VERSION ""

NS_ :

BS_:

BU_: MASTER_BMS SUB_BMS
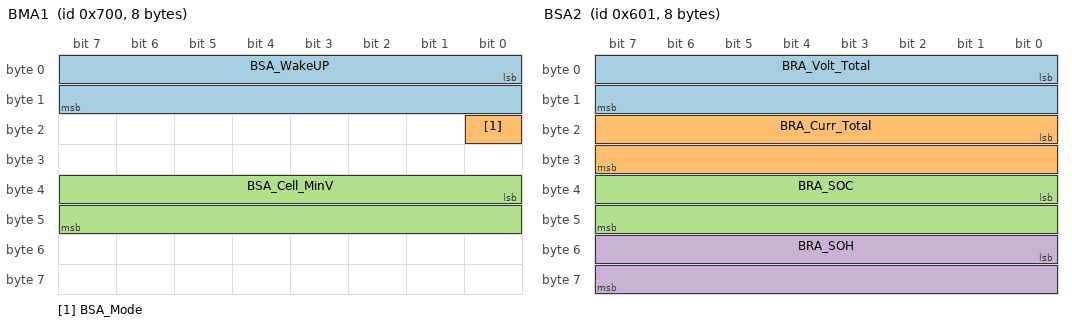
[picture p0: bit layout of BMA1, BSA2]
BO_ 1792 BMA1: 8 MASTER_BMS
 SG_ BSA_WakeUP : 0|16@1+ (1.0,0) [0.0|1.0] "flag"  SUB_BMS
 SG_ BSA_Mode : 16|1@1+ (1.0,0) [0.0|1.0] "flag"  SUB_BMS
 SG_ BSA_Cell_MinV : 32|16@1+ (0.001,0) [2.8|4.5] "V"  SUB_BMS
BO_ 1536 BSA1: 8 SUB_BMS
 SG_ BRA_Normal_Volt : 16|16@1+ (0.1,0) [0.0|100.0] "V"  MASTER_BMS
 SG_ BRA_Capacity : 32|16@1+ (0.1,0) [30.0|60.0] "Ah"  MASTER_BMS
BO_ 1537 BSA2: 8 SUB_BMS
 SG_ BRA_Volt_Total : 0|16@1+ (0.1,0) [40.0|120.0] "V"  MASTER_BMS
 SG_ BRA_Curr_Total : 16|16@1- (0.1,0) [-500.0|500.0] "A"  MASTER_BMS
 SG_ BRA_SOC : 32|16@1+ (0.1,0) [0.0|120.0] "%"  MASTER_BMS
 SG_ BRA_SOH : 48|16@1- (0.1,0) [0.0|100.0] "%"  MASTER_BMS
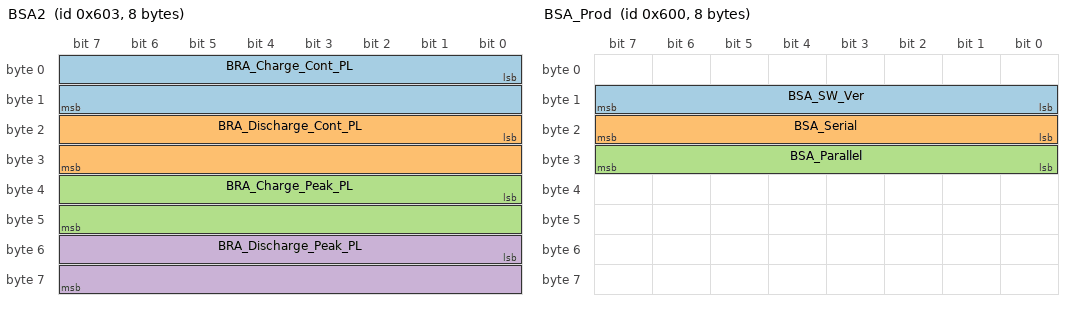
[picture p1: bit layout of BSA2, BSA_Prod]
BO_ 1539 BSA2: 8 SUB_BMS
 SG_ BRA_Charge_Cont_PL : 0|16@1+ (1.0,0) [10.0|5000.0] "W"  MASTER_BMS
 SG_ BRA_Discharge_Cont_PL : 16|16@1+ (1.0,0) [10.0|30000.0] "W"  MASTER_BMS
 SG_ BRA_Charge_Peak_PL : 32|16@1+ (1.0,0) [10.0|6000.0] "W"  MASTER_BMS
 SG_ BRA_Discharge_Peak_PL : 48|16@1+ (1.0,0) [10.0|40000.0] "W"  MASTER_BMS
BO_ 1543 BSA4: 8 SUB_BMS
 SG_ BSA_Cell_MaxV Location : 0|16@1+ (1.0,0) [0.0|20.0] "BM"  MASTER_BMS
 SG_ BSA_Cell_MinV Location : 16|16@1+ (0.01,0) [57.599999999999994|108.0] "V"  MASTER_BMS
 SG_ BSA_Cell_MaxT Location : 32|16@1+ (0.001,0) [2.5|4.5] "V"  MASTER_BMS
 SG_ BSA_Cell_MinT Location : 48|16@1+ (0.001,0) [2.5|4.5] "V"  MASTER_BMS
BO_ 1538 BSA_Calc: 8 SUB_BMS
 SG_ BSA_Divice_Status : 0|8@1+ (1.0,0) [0.0|4.0] "State"  MASTER_BMS
BO_ 1536 BSA_Prd: 8 SUB_BMS
 SG_ BSA_Type : 0|8@1+ (1.0,0) [0.0|10.0] ""  MASTER_BMS
BO_ 1536 BSA_Prod: 8 SUB_BMS
 SG_ BSA_SW_Ver : 8|8@1- (1.0,0) [1.0|10.0] "VER"  MASTER_BMS
 SG_ BSA_Serial : 16|8@1- (1.0,0) [0.0|200.0] "S"  MASTER_BMS
 SG_ BSA_Parallel : 24|8@1+ (1.0,0) [0.0|10.0] "P"  MASTER_BMS
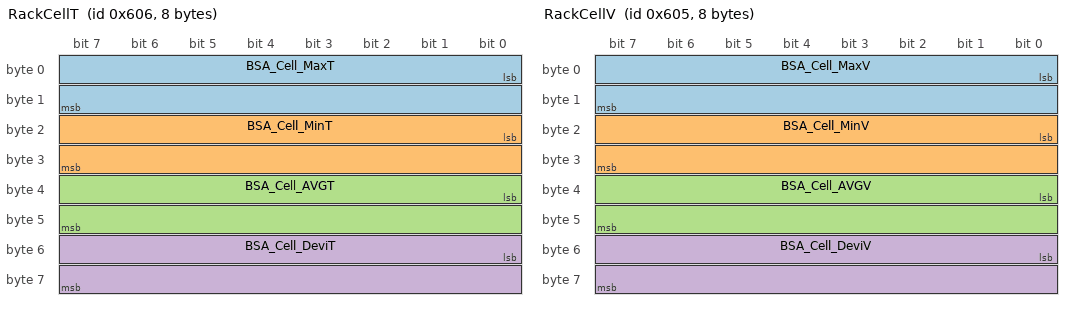
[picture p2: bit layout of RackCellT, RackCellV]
BO_ 1542 RackCellT: 8 SUB_BMS
 SG_ BSA_Cell_MaxT : 0|16@1- (0.1,0) [-40.0|100.0] "℃"  MASTER_BMS
 SG_ BSA_Cell_MinT : 16|16@1- (0.1,0) [-40.0|100.0] "℃"  MASTER_BMS
 SG_ BSA_Cell_AVGT : 32|16@1- (0.1,0) [-40.0|100.0] "℃"  MASTER_BMS
 SG_ BSA_Cell_DeviT : 48|16@1+ (0.1,0) [0.0|25.0] "℃"  MASTER_BMS
BO_ 1541 RackCellV: 8 SUB_BMS
 SG_ BSA_Cell_MaxV : 0|16@1+ (0.001,0) [2.8|4.5] "V"  MASTER_BMS
 SG_ BSA_Cell_MinV : 16|16@1+ (0.001,0) [2.8|4.5] "V"  MASTER_BMS
 SG_ BSA_Cell_AVGV : 32|16@1+ (0.001,0) [2.8|4.5] "V"  MASTER_BMS
 SG_ BSA_Cell_DeviV : 48|16@1+ (1.0,0) [0.0|500.0] "mV"  MASTER_BMS
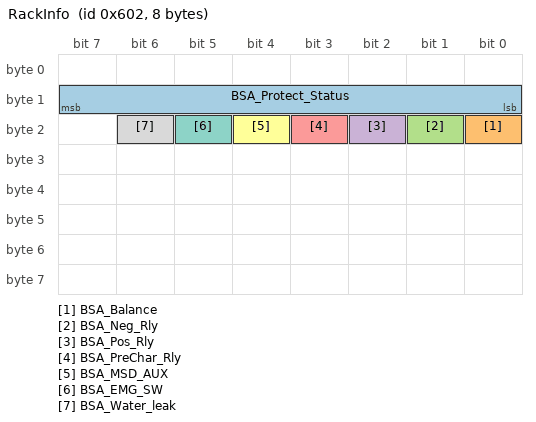
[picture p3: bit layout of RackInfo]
BO_ 1538 RackInfo: 8 SUB_BMS
 SG_ BSA_Protect_Status : 8|8@1+ (1.0,0) [0.0|4.0] "State"  MASTER_BMS
 SG_ BSA_Balance : 16|1@1+ (1.0,0) [0.0|1.0] "flag"  MASTER_BMS
 SG_ BSA_Neg_Rly : 17|1@1+ (1.0,0) [0.0|1.0] "flag"  MASTER_BMS
 SG_ BSA_Pos_Rly : 18|1@1+ (1.0,0) [0.0|1.0] "flag"  MASTER_BMS
 SG_ BSA_PreChar_Rly : 19|1@1+ (1.0,0) [0.0|1.0] "flag"  MASTER_BMS
 SG_ BSA_MSD_AUX : 20|1@1+ (1.0,0) [0.0|1.0] "flag"  MASTER_BMS
 SG_ BSA_EMG_SW : 21|1@1+ (1.0,0) [0.0|1.0] "flag"  MASTER_BMS
 SG_ BSA_Water_leak : 22|1@1+ (1.0,0) [0.0|1.0] "flag"  MASTER_BMS
BO_ 1539 RackPrtState: 8 SUB_BMS
 SG_ BSA_Wn_Dischager_OC : 0|1@1+ (1.0,0) [0.0|1.0] "flag"  MASTER_BMS
 SG_ BSA_Wn_Chager_OC : 1|1@1+ (1.0,0) [0.0|1.0] "flag"  MASTER_BMS
 SG_ BSA_Wn_SOC_OV : 2|1@1+ (1.0,0) [0.0|1.0] "flag"  MASTER_BMS
 SG_ BSA_Wn_SOC_Un : 3|1@1+ (1.0,0) [0.0|1.0] "flag"  MASTER_BMS
 SG_ BSA_Wn_OV : 4|1@1+ (1.0,0) [0.0|1.0] "flag"  MASTER_BMS
 SG_ BSA_Wn_UV : 5|1@1+ (1.0,0) [0.0|1.0] "flag"  MASTER_BMS
 SG_ BSA_Wn_Cell_OV : 6|1@1+ (1.0,0) [0.0|1.0] "flag"  MASTER_BMS
 SG_ BSA_Wn_Cell_UV : 7|1@1+ (1.0,0) [0.0|1.0] "flag"  MASTER_BMS
 SG_ BSA_Wn_Cell_UnbalV : 8|1@1+ (1.0,0) [0.0|1.0] "flag"  MASTER_BMS
 SG_ BSA_Wn_DisCharger_Cell_OT : 9|1@1+ (1.0,0) [0.0|1.0] "flag"  MASTER_BMS
 SG_ BSA_Wn_Charger_Cell_OT : 10|1@1+ (1.0,0) [0.0|1.0] "flag"  MASTER_BMS
 SG_ BSA_Wn_DisCharger_Cell_UT : 11|1@1+ (1.0,0) [0.0|1.0] "flag"  MASTER_BMS
 SG_ BSA_Wn_Charger_Cell_UT : 12|1@1+ (1.0,0) [0.0|1.0] "flag"  MASTER_BMS
 SG_ BSA_Wn_Cell_UnbalT : 13|1@1+ (1.0,0) [0.0|1.0] "flag"  MASTER_BMS
 SG_ BSA_FLT_Dischager_OC : 16|1@1+ (1.0,0) [0.0|1.0] "flag"  MASTER_BMS
 SG_ BSA_FLT_Chager_OC : 17|1@1+ (1.0,0) [0.0|1.0] "flag"  MASTER_BMS
 SG_ BSA_FLT_SOC_OV : 18|1@1+ (1.0,0) [0.0|1.0] "flag"  MASTER_BMS
 SG_ BSA_FLT_SOC_Un : 19|1@1+ (1.0,0) [0.0|1.0] "flag"  MASTER_BMS
 SG_ BSA_FLT_OV : 20|1@1+ (1.0,0) [0.0|1.0] "flag"  MASTER_BMS
 SG_ BSA_FLT_UV : 21|1@1+ (1.0,0) [0.0|1.0] "flag"  MASTER_BMS
 SG_ BSA_FLT_Cell_OV : 22|1@1+ (1.0,0) [0.0|1.0] "flag"  MASTER_BMS
 SG_ BSA_FLT_Cell_UV : 23|1@1+ (1.0,0) [0.0|1.0] "flag"  MASTER_BMS
 SG_ BSA_FLT_Cell_UnbalV : 24|1@1+ (1.0,0) [0.0|1.0] "flag"  MASTER_BMS
 SG_ BSA_FLT_DisCharger_Cell_OT : 25|1@1+ (1.0,0) [0.0|1.0] "flag"  MASTER_BMS
 SG_ BSA_FLT_Charger_Cell_OT : 26|1@1+ (1.0,0) [0.0|1.0] "flag"  MASTER_BMS
 SG_ BSA_FLT_DisCharger_Cell_UT : 27|1@1+ (1.0,0) [0.0|1.0] "flag"  MASTER_BMS
 SG_ BSA_FLT_Charger_Cell_UT : 28|1@1+ (1.0,0) [0.0|1.0] "flag"  MASTER_BMS
 SG_ BSA_FLT_Cell_UnbalT : 29|1@1+ (1.0,0) [0.0|1.0] "flag"  MASTER_BMS
 SG_ BSA_FLT_Discharger_UnbaPWR : 30|1@1+ (1.0,0) [0.0|1.0] "flag"  MASTER_BMS
 SG_ BSA_FLT_Charger_UnbaPWR : 31|1@1+ (1.0,0) [0.0|1.0] "flag"  MASTER_BMS
 SG_ BSA_Prtct_Dischager_OC : 32|1@1+ (1.0,0) [0.0|1.0] "flag"  MASTER_BMS
 SG_ BSA_Prtct_Chager_OC : 33|1@1+ (1.0,0) [0.0|1.0] "flag"  MASTER_BMS
 SG_ BSA_Prtct_SOC_OV : 34|1@1+ (1.0,0) [0.0|1.0] "flag"  MASTER_BMS
 SG_ BSA_Prtct_SOC_Un : 35|1@1+ (1.0,0) [0.0|1.0] "flag"  MASTER_BMS
 SG_ BSA_Prtct_OV : 36|1@1+ (1.0,0) [0.0|1.0] "flag"  MASTER_BMS
 SG_ BSA_Prtct_UV : 37|1@1+ (1.0,0) [0.0|1.0] "flag"  MASTER_BMS
 SG_ BSA_Prtct_DisCharger_Cell_OT : 41|1@1+ (1.0,0) [0.0|1.0] "flag"  MASTER_BMS
 SG_ BSA_Prtct_DisCharger_Cell_UT : 43|1@1+ (1.0,0) [0.0|1.0] "flag"  MASTER_BMS
 SG_ BSA_Prtct_Charger_Cell_UT : 44|1@1+ (1.0,0) [0.0|1.0] "flag"  MASTER_BMS
 SG_ BSA_Prtct_Cell_UnbalT : 45|1@1+ (1.0,0) [0.0|1.0] "flag"  MASTER_BMS
 SG_ BSA_Prtct_Discharger_UnbaPWR : 46|1@1+ (1.0,0) [0.0|1.0] "flag"  MASTER_BMS
 SG_ BSA_Prtct_Charger_UnbaPWR : 47|1@1+ (1.0,0) [0.0|1.0] "flag"  MASTER_BMS
 SG_ BSA_Prtct_Rly_Err : 48|1@1+ (1.0,0) [0.0|1.0] "flag"  MASTER_BMS
 SG_ BSA_Prtct_IN_COM_Err : 49|1@1+ (1.0,0) [0.0|1.0] "flag"  MASTER_BMS
 SG_ BSA_Prtct_EX_COM_Err : 50|1@1+ (1.0,0) [0.0|1.0] "flag"  MASTER_BMS
 SG_ BSA_Prtct_Water_Leak_Err : 52|1@1+ (1.0,0) [0.0|1.0] "flag"  MASTER_BMS
 SG_ BSA_Prtct_EMS_SW_Err : 53|1@1+ (1.0,0) [0.0|1.0] "flag"  MASTER_BMS
